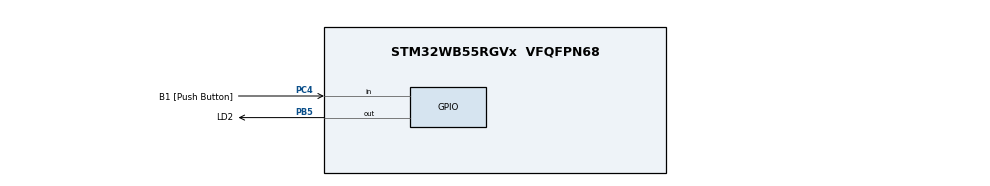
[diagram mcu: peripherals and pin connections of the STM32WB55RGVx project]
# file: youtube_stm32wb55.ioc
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Mcu.Family=STM32WB
Mcu.Name=STM32WB55RGVx
Mcu.Package=VFQFPN68
NVIC.HSEM_IRQn=true\:0\:0\:false\:false\:true\:false\:true\:true
NVIC.IPCC_C1_RX_IRQn=true\:0\:0\:false\:false\:true\:true\:true\:true
NVIC.IPCC_C1_TX_IRQn=true\:0\:0\:false\:false\:true\:true\:true\:true
NVIC.PriorityGroup=NVIC_PRIORITYGROUP_4
NVIC.RCC_IRQn=true\:0\:0\:false\:false\:true\:true\:false\:true
NVIC.RTC_WKUP_IRQn=true\:0\:0\:false\:false\:true\:true\:true\:true
OSC_IN.Mode=HSE-External-Oscillator
OSC_IN.Signal=RCC_OSC_IN
OSC_OUT.Mode=HSE-External-Oscillator
OSC_OUT.Signal=RCC_OSC_OUT
PA13.Mode=Serial_Wire
PA13.Signal=SYS_JTMS-SWDIO
PA14.Mode=Serial_Wire
PA14.Signal=SYS_JTCK-SWCLK
PB5.GPIO_Label=LD2
PB5.Signal=GPIO_Output
PC14-OSC32_IN.Mode=LSE-External-Oscillator
PC14-OSC32_IN.Signal=RCC_OSC32_IN
PC15-OSC32_OUT.Mode=LSE-External-Oscillator
PC15-OSC32_OUT.Signal=RCC_OSC32_OUT
PC4.GPIO_Label=B1 [Push Button]
PC4.GPIO_PuPd=GPIO_PULLUP
PC4.Signal=GPIO_Input
ProjectManager.HeapSize=0x200
ProjectManager.StackSize=0x400
ProjectManager.TargetToolchain=STM32CubeIDE
RCC.ADCFreq_Value=128000000
RCC.AHBFreq_Value=32000000
RCC.APB1Freq_Value=32000000
RCC.APB1TimFreq_Value=32000000
RCC.APB2Freq_Value=32000000
RCC.APB2TimFreq_Value=32000000
RCC.APB3Freq_Value=16000000
RCC.CortexFreq_Value=32000000
RCC.HCLKFreq_Value=32000000
RCC.HSE_VALUE=32000000
RCC.HSI48_VALUE=48000000
RCC.HSI_VALUE=16000000
RCC.MSIClockRange=RCC_MSIRANGE_10
RCC.RFWKPClockSelection=RCC_RFWKPCLKSOURCE_LSE
RCC.RTCClockSelection=RCC_RTCCLKSOURCE_LSE
RCC.SYSCLKFreq_VALUE=32000000
RCC.USBFreq_Value=128000000
RCC.VCOOutputFreq_Value=256000000
RF1.Mode=RF1_Activate
RF1.Signal=RF_RF1
STM32_WPAN.AD_SERVICE_CLASS_UUID_1=18 0D
STM32_WPAN.AD_SERVICE_CLASS_UUID_1_INV=[0D, 18]
STM32_WPAN.AD_TYPE_COMPLETE_LOCAL_NAME=myBLE
STM32_WPAN.AD_TYPE_COMPLETE_LOCAL_NAME_LENGTH=6
STM32_WPAN.CFG_GAP_DEVICE_NAME=MY_APPU
STM32_WPAN.CFG_GAP_DEVICE_NAME_LENGTH=7
STM32_WPAN.CFG_PRIVACY=PRIVACY_DISABLED
STM32_WPAN.CUSTOM_P2P_SERVER=Disabled
STM32_WPAN.CUSTOM_TEMPLATE=Enabled
STM32_WPAN.INCLUDE_AD_TYPE_16_BIT_SERV_UUID_CMPLT_LIST=1
STM32_WPAN.INCLUDE_AD_TYPE_COMPLETE_LOCAL_NAME=1
STM32_WPAN.INCLUDE_AD_TYPE_MANUFACTURER_SPECIFIC_DATA=1
STM32_WPAN.INCLUDE_AD_TYPE_TX_POWER_LEVEL=1
STM32_WPAN.NUMBER_OF_SERVICES=1
STM32_WPAN.SERVICE1_CHAR1_GATT_NOTIFY_READ_REQ_AND_WAIT_FOR_APPL_RESP=\ 
STM32_WPAN.SERVICE1_CHAR1_GATT_NOTIFY_WRITE_REQ_AND_WAIT_FOR_APPL_RESP=\ 
STM32_WPAN.SERVICE1_CHAR1_LONG_NAME=myCharWrite
STM32_WPAN.SERVICE1_CHAR1_PROP_WRITE=CHAR_PROP_WRITE
STM32_WPAN.SERVICE1_CHAR1_SHORT_NAME=myCharWrite
STM32_WPAN.SERVICE1_CHAR2_GATT_NOTIFY_NOTIFICATION_COMPLETION=GATT_NOTIFY_NOTIFICATION_COMPLETION
STM32_WPAN.SERVICE1_CHAR2_LONG_NAME=myCharNotify
STM32_WPAN.SERVICE1_CHAR2_PROP_BROADCAST=CHAR_PROP_BROADCAST
STM32_WPAN.SERVICE1_CHAR2_PROP_NOTIFY=CHAR_PROP_NOTIFY
STM32_WPAN.SERVICE1_CHAR2_SHORT_NAME=myCharNotify
STM32_WPAN.SERVICE1_CHAR2_UUID=00 01
STM32_WPAN.SERVICE1_LONG_NAME=myBLE
STM32_WPAN.SERVICE1_NUMBER_OF_CHARACTERISTICS=2
STM32_WPAN.SERVICE1_SHORT_NAME=myBLE
VP_HSEM_VS_HSEM.Mode=HSEM_Activate
VP_IPCC_VS_IPCC.Mode=IPCC_Activate
VP_MEMORYMAP_VS_MEMORYMAP.Mode=CurAppReg
VP_RTC_VS_RTC_Activate.Mode=RTC_Enabled
VP_RTC_VS_RTC_WakeUp_intern.Mode=WakeUp
VP_SEQUENCER_VS_SEQUENCER.Mode=SEQUENCER_Enabled
VP_STM32_WPAN_VS_BLE_HOST.Mode=STM32_WPAN_Enabled
VP_TINY_LPM_VS_TINY_LPM.Mode=TINY_LPM_Enabled
board=custom

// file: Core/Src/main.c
/* USER CODE BEGIN Header */
/**
  ******************************************************************************
  * @file           : main.c
  * @brief          : Main program body
  ******************************************************************************
  * @attention
  *
  * Copyright (c) 2024 STMicroelectronics.
  * All rights reserved.
  *
  * This software is licensed under terms that can be found in the LICENSE file
  * in the root directory of this software component.
  * If no LICENSE file comes with this software, it is provided AS-IS.
  *
  ******************************************************************************
  */
/* USER CODE END Header */
#include "main.h"
#include "app_ble.h"
#include "ble_hci_le.h"

IPCC_HandleTypeDef hipcc;

RTC_HandleTypeDef hrtc;

/* USER CODE BEGIN PV */
uint8_t abc = 0;
/* USER CODE END PV */

void SystemClock_Config(void);
void PeriphCommonClock_Config(void);
static void MX_GPIO_Init(void);
static void MX_IPCC_Init(void);
static void MX_RTC_Init(void);
static void MX_RF_Init(void);

int main(void)
{

  /* MCU Configuration--------------------------------------------------------*/

  /* Reset of all peripherals, Initializes the Flash interface and the Systick. */
  HAL_Init();
  /* Config code for STM32_WPAN (HSE Tuning must be done before system clock configuration) */
  MX_APPE_Config();

  /* Configure the system clock */
  SystemClock_Config();

/* Configure the peripherals common clocks */
  PeriphCommonClock_Config();

  /* IPCC initialisation */
  MX_IPCC_Init();

  /* Initialize all configured peripherals */
  MX_GPIO_Init();
  MX_RTC_Init();
  MX_RF_Init();

  /* Init code for STM32_WPAN */
  MX_APPE_Init();

  /* Infinite loop */
  /* USER CODE BEGIN WHILE */
//  uint8_t a_AdvData[19] =
//  {
//    2, AD_TYPE_TX_POWER_LEVEL, 0 /* -0.15dBm */, /* Transmission Power */
//    6, AD_TYPE_COMPLETE_LOCAL_NAME, 'm', 'y', 'B', 'L', 'E',  /* Complete name */
//    3, AD_TYPE_16_BIT_SERV_UUID_CMPLT_LIST, 0x0D, 0x18,
//    4, AD_TYPE_MANUFACTURER_SPECIFIC_DATA, 0x30, 0x00, 0x00 /*  */,
//  };
  while (1)
  {
	  abc++;
	  if(abc > 10) {
		  abc = 0;
	  }
//	  abc = 1;
	  a_AdvData[17] = abc;
	  hci_le_set_advertising_data(sizeof(a_AdvData), (uint8_t*) a_AdvData);
//	  aci_gap_update_adv_data(sizeof(a_AdvData), (uint8_t*) a_AdvData);
//	  hci_le_set_advertising_data(19, a_AdvData);
    /* USER CODE END WHILE */
    MX_APPE_Process();

  }
}

void SystemClock_Config(void)
{
  RCC_OscInitTypeDef RCC_OscInitStruct = {0};
  RCC_ClkInitTypeDef RCC_ClkInitStruct = {0};

  /** Configure LSE Drive Capability
  */
  HAL_PWR_EnableBkUpAccess();
  __HAL_RCC_LSEDRIVE_CONFIG(RCC_LSEDRIVE_MEDIUMHIGH);

  /** Configure the main internal regulator output voltage
  */
  __HAL_PWR_VOLTAGESCALING_CONFIG(PWR_REGULATOR_VOLTAGE_SCALE1);

  /** Initializes the RCC Oscillators according to the specified parameters
  * in the RCC_OscInitTypeDef structure.
  */
  RCC_OscInitStruct.OscillatorType = RCC_OSCILLATORTYPE_HSI|RCC_OSCILLATORTYPE_HSE
                              |RCC_OSCILLATORTYPE_LSE|RCC_OSCILLATORTYPE_MSI;
  RCC_OscInitStruct.HSEState = RCC_HSE_ON;
  RCC_OscInitStruct.LSEState = RCC_LSE_ON;
  RCC_OscInitStruct.HSIState = RCC_HSI_ON;
  RCC_OscInitStruct.MSIState = RCC_MSI_ON;
  RCC_OscInitStruct.HSICalibrationValue = RCC_HSICALIBRATION_DEFAULT;
  RCC_OscInitStruct.MSICalibrationValue = RCC_MSICALIBRATION_DEFAULT;
  RCC_OscInitStruct.MSIClockRange = RCC_MSIRANGE_10;
  RCC_OscInitStruct.PLL.PLLState = RCC_PLL_NONE;
  if (HAL_RCC_OscConfig(&RCC_OscInitStruct) != HAL_OK)
  {
    Error_Handler();
  }

  /** Configure the SYSCLKSource, HCLK, PCLK1 and PCLK2 clocks dividers
  */
  RCC_ClkInitStruct.ClockType = RCC_CLOCKTYPE_HCLK4|RCC_CLOCKTYPE_HCLK2
                              |RCC_CLOCKTYPE_HCLK|RCC_CLOCKTYPE_SYSCLK
                              |RCC_CLOCKTYPE_PCLK1|RCC_CLOCKTYPE_PCLK2;
  RCC_ClkInitStruct.SYSCLKSource = RCC_SYSCLKSOURCE_MSI;
  RCC_ClkInitStruct.AHBCLKDivider = RCC_SYSCLK_DIV1;
  RCC_ClkInitStruct.APB1CLKDivider = RCC_HCLK_DIV1;
  RCC_ClkInitStruct.APB2CLKDivider = RCC_HCLK_DIV1;
  RCC_ClkInitStruct.AHBCLK2Divider = RCC_SYSCLK_DIV1;
  RCC_ClkInitStruct.AHBCLK4Divider = RCC_SYSCLK_DIV1;

  if (HAL_RCC_ClockConfig(&RCC_ClkInitStruct, FLASH_LATENCY_1) != HAL_OK)
  {
    Error_Handler();
  }
}

void PeriphCommonClock_Config(void)
{
  RCC_PeriphCLKInitTypeDef PeriphClkInitStruct = {0};

  /** Initializes the peripherals clock
  */
  PeriphClkInitStruct.PeriphClockSelection = RCC_PERIPHCLK_SMPS|RCC_PERIPHCLK_RFWAKEUP;
  PeriphClkInitStruct.RFWakeUpClockSelection = RCC_RFWKPCLKSOURCE_LSE;
  PeriphClkInitStruct.SmpsClockSelection = RCC_SMPSCLKSOURCE_HSI;
  PeriphClkInitStruct.SmpsDivSelection = RCC_SMPSCLKDIV_RANGE1;

  if (HAL_RCCEx_PeriphCLKConfig(&PeriphClkInitStruct) != HAL_OK)
  {
    Error_Handler();
  }
}

static void MX_IPCC_Init(void)
{

  hipcc.Instance = IPCC;
  if (HAL_IPCC_Init(&hipcc) != HAL_OK)
  {
    Error_Handler();
  }

}

static void MX_RF_Init(void)
{

}

static void MX_RTC_Init(void)
{

  /** Initialize RTC Only
  */
  hrtc.Instance = RTC;
  hrtc.Init.HourFormat = RTC_HOURFORMAT_24;
  hrtc.Init.AsynchPrediv = CFG_RTC_ASYNCH_PRESCALER;
  hrtc.Init.SynchPrediv = CFG_RTC_SYNCH_PRESCALER;
  hrtc.Init.OutPut = RTC_OUTPUT_DISABLE;
  hrtc.Init.OutPutPolarity = RTC_OUTPUT_POLARITY_HIGH;
  hrtc.Init.OutPutType = RTC_OUTPUT_TYPE_OPENDRAIN;
  hrtc.Init.OutPutRemap = RTC_OUTPUT_REMAP_NONE;
  if (HAL_RTC_Init(&hrtc) != HAL_OK)
  {
    Error_Handler();
  }

  /** Enable the WakeUp
  */
  if (HAL_RTCEx_SetWakeUpTimer_IT(&hrtc, 0, RTC_WAKEUPCLOCK_RTCCLK_DIV16) != HAL_OK)
  {
    Error_Handler();
  }

}

static void MX_GPIO_Init(void)
{
  GPIO_InitTypeDef GPIO_InitStruct = {0};

  /* GPIO Ports Clock Enable */
  __HAL_RCC_GPIOC_CLK_ENABLE();
  __HAL_RCC_GPIOA_CLK_ENABLE();
  __HAL_RCC_GPIOB_CLK_ENABLE();

  /*Configure GPIO pin Output Level */
  HAL_GPIO_WritePin(LD2_GPIO_Port, LD2_Pin, GPIO_PIN_RESET);

  /*Configure GPIO pin : B1_Pin */
  GPIO_InitStruct.Pin = B1_Pin;
  GPIO_InitStruct.Mode = GPIO_MODE_INPUT;
  GPIO_InitStruct.Pull = GPIO_PULLUP;
  HAL_GPIO_Init(B1_GPIO_Port, &GPIO_InitStruct);

  /*Configure GPIO pin : LD2_Pin */
  GPIO_InitStruct.Pin = LD2_Pin;
  GPIO_InitStruct.Mode = GPIO_MODE_OUTPUT_PP;
  GPIO_InitStruct.Pull = GPIO_NOPULL;
  GPIO_InitStruct.Speed = GPIO_SPEED_FREQ_LOW;
  HAL_GPIO_Init(LD2_GPIO_Port, &GPIO_InitStruct);

}

void Error_Handler(void)
{
  __disable_irq();
  while (1)
  {
  }
}
